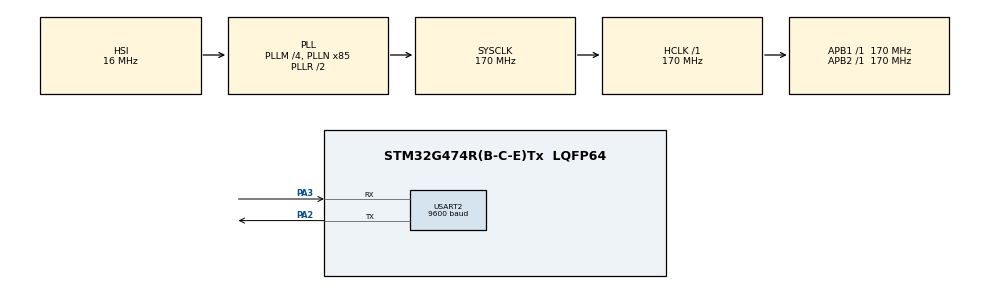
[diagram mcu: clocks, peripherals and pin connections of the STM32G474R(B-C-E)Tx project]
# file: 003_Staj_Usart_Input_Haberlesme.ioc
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Mcu.Family=STM32G4
Mcu.Name=STM32G474R(B-C-E)Tx
Mcu.Package=LQFP64
NVIC.PriorityGroup=NVIC_PRIORITYGROUP_4
PA13.Mode=Serial_Wire
PA13.Signal=SYS_JTMS-SWDIO
PA14.Mode=Serial_Wire
PA14.Signal=SYS_JTCK-SWCLK
PA2.Mode=Asynchronous
PA2.Signal=USART2_TX
PA2.TagName=VCP_TX
PA3.Mode=Asynchronous
PA3.Signal=USART2_RX
PA3.TagName=VCP_RX
PA5.TagName=LD2
PC13.TagName=B1
PC14-OSC32_IN.Mode=LSE-External-Oscillator
PC14-OSC32_IN.Signal=RCC_OSC32_IN
PC15-OSC32_OUT.Mode=LSE-External-Oscillator
PC15-OSC32_OUT.Signal=RCC_OSC32_OUT
PF0-OSC_IN.Mode=HSE-External-Oscillator
PF0-OSC_IN.Signal=RCC_OSC_IN
PF1-OSC_OUT.Mode=HSE-External-Oscillator
PF1-OSC_OUT.Signal=RCC_OSC_OUT
ProjectManager.HeapSize=0x200
ProjectManager.StackSize=0x400
ProjectManager.TargetToolchain=STM32CubeIDE
RCC.ADC12Freq_Value=170000000
RCC.ADC345Freq_Value=170000000
RCC.AHBFreq_Value=170000000
RCC.APB1Freq_Value=170000000
RCC.APB1TimFreq_Value=170000000
RCC.APB2Freq_Value=170000000
RCC.APB2TimFreq_Value=170000000
RCC.CortexFreq_Value=170000000
RCC.EXTERNAL_CLOCK_VALUE=12288000
RCC.HCLKFreq_Value=170000000
RCC.HSE_VALUE=24000000
RCC.HSI48_VALUE=48000000
RCC.HSI_VALUE=16000000
RCC.PLLM=RCC_PLLM_DIV4
RCC.PLLN=85
RCC.RTCClockSelection=RCC_RTCCLKSOURCE_LSE
RCC.SYSCLKFreq_VALUE=170000000
RCC.SYSCLKSource=RCC_SYSCLKSOURCE_PLLCLK
RCC.USBFreq_Value=170000000
RCC.VCOOutputFreq_Value=340000000
USART2.BaudRate=9600
USART2.VirtualMode-Asynchronous=VM_ASYNC
VP_SYS_VS_DBSignals.Mode=DisableDeadBatterySignals
board=NUCLEO-G474RE

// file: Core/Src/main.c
/* USER CODE BEGIN Header */
/**
  ******************************************************************************
  * @file           : main.c
  * @brief          : Main program body
  ******************************************************************************
  * @attention
  *
  * Copyright (c) 2024 STMicroelectronics.
  * All rights reserved.
  *
  * This software is licensed under terms that can be found in the LICENSE file
  * in the root directory of this software component.
  * If no LICENSE file comes with this software, it is provided AS-IS.
  *
  ******************************************************************************
  */
/* USER CODE END Header */
#include "main.h"

/* USER CODE BEGIN Includes */
#include "string.h"

/* USER CODE END Includes */

/* USER CODE BEGIN PTD */
uint8_t rxdata; /*gelen veri*/
int sayi=0;
/* USER CODE END PTD */

UART_HandleTypeDef huart2;

void SystemClock_Config(void);
static void MX_GPIO_Init(void);
static void MX_USART2_UART_Init(void);

int main(void)
{

  /* MCU Configuration--------------------------------------------------------*/

  /* Reset of all peripherals, Initializes the Flash interface and the Systick. */
  HAL_Init();

  /* Configure the system clock */
  SystemClock_Config();

  /* Initialize all configured peripherals */
  MX_GPIO_Init();
  MX_USART2_UART_Init();

  /* Infinite loop */
  while (1)
  {

    /* USER CODE BEGIN 3 */

	  if(HAL_UART_Receive(&huart2, &rxdata, 1, HAL_MAX_DELAY)== HAL_OK){

		  if(rxdata=='a'){
			  sayi++;

		  }
		  if(rxdata =='b'){
		  			  sayi--;
		  		  }
	  }

		  char liste[50];
		  sprintf(liste,"SAYİ: %d \n",sayi);
		  HAL_UART_Transmit(&huart2, (uint8_t*)liste, strlen(liste), HAL_MAX_DELAY);

  }
  /* USER CODE END 3 */
}

void SystemClock_Config(void)
{
  RCC_OscInitTypeDef RCC_OscInitStruct = {0};
  RCC_ClkInitTypeDef RCC_ClkInitStruct = {0};

  /** Configure the main internal regulator output voltage
  */
  HAL_PWREx_ControlVoltageScaling(PWR_REGULATOR_VOLTAGE_SCALE1_BOOST);

  /** Initializes the RCC Oscillators according to the specified parameters
  * in the RCC_OscInitTypeDef structure.
  */
  RCC_OscInitStruct.OscillatorType = RCC_OSCILLATORTYPE_HSI;
  RCC_OscInitStruct.HSIState = RCC_HSI_ON;
  RCC_OscInitStruct.HSICalibrationValue = RCC_HSICALIBRATION_DEFAULT;
  RCC_OscInitStruct.PLL.PLLState = RCC_PLL_ON;
  RCC_OscInitStruct.PLL.PLLSource = RCC_PLLSOURCE_HSI;
  RCC_OscInitStruct.PLL.PLLM = RCC_PLLM_DIV4;
  RCC_OscInitStruct.PLL.PLLN = 85;
  RCC_OscInitStruct.PLL.PLLP = RCC_PLLP_DIV2;
  RCC_OscInitStruct.PLL.PLLQ = RCC_PLLQ_DIV2;
  RCC_OscInitStruct.PLL.PLLR = RCC_PLLR_DIV2;
  if (HAL_RCC_OscConfig(&RCC_OscInitStruct) != HAL_OK)
  {
    Error_Handler();
  }

  /** Initializes the CPU, AHB and APB buses clocks
  */
  RCC_ClkInitStruct.ClockType = RCC_CLOCKTYPE_HCLK|RCC_CLOCKTYPE_SYSCLK
                              |RCC_CLOCKTYPE_PCLK1|RCC_CLOCKTYPE_PCLK2;
  RCC_ClkInitStruct.SYSCLKSource = RCC_SYSCLKSOURCE_PLLCLK;
  RCC_ClkInitStruct.AHBCLKDivider = RCC_SYSCLK_DIV1;
  RCC_ClkInitStruct.APB1CLKDivider = RCC_HCLK_DIV1;
  RCC_ClkInitStruct.APB2CLKDivider = RCC_HCLK_DIV1;

  if (HAL_RCC_ClockConfig(&RCC_ClkInitStruct, FLASH_LATENCY_4) != HAL_OK)
  {
    Error_Handler();
  }
}

static void MX_USART2_UART_Init(void)
{

  huart2.Instance = USART2;
  huart2.Init.BaudRate = 9600;
  huart2.Init.WordLength = UART_WORDLENGTH_8B;
  huart2.Init.StopBits = UART_STOPBITS_1;
  huart2.Init.Parity = UART_PARITY_NONE;
  huart2.Init.Mode = UART_MODE_TX_RX;
  huart2.Init.HwFlowCtl = UART_HWCONTROL_NONE;
  huart2.Init.OverSampling = UART_OVERSAMPLING_16;
  huart2.Init.OneBitSampling = UART_ONE_BIT_SAMPLE_DISABLE;
  huart2.Init.ClockPrescaler = UART_PRESCALER_DIV1;
  huart2.AdvancedInit.AdvFeatureInit = UART_ADVFEATURE_NO_INIT;
  if (HAL_UART_Init(&huart2) != HAL_OK)
  {
    Error_Handler();
  }
  if (HAL_UARTEx_SetTxFifoThreshold(&huart2, UART_TXFIFO_THRESHOLD_1_8) != HAL_OK)
  {
    Error_Handler();
  }
  if (HAL_UARTEx_SetRxFifoThreshold(&huart2, UART_RXFIFO_THRESHOLD_1_8) != HAL_OK)
  {
    Error_Handler();
  }
  if (HAL_UARTEx_DisableFifoMode(&huart2) != HAL_OK)
  {
    Error_Handler();
  }

}

static void MX_GPIO_Init(void)
{

  /* GPIO Ports Clock Enable */
  __HAL_RCC_GPIOC_CLK_ENABLE();
  __HAL_RCC_GPIOF_CLK_ENABLE();
  __HAL_RCC_GPIOA_CLK_ENABLE();

}

void Error_Handler(void)
{
  __disable_irq();
  while (1)
  {
  }
}
